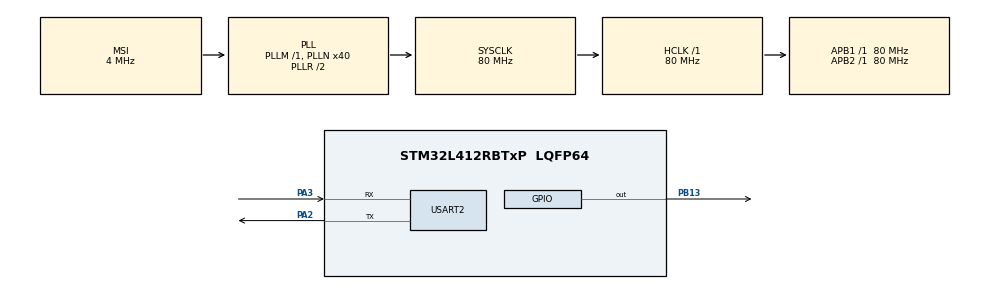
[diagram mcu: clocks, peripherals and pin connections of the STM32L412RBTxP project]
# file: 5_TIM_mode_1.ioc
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Dma.Request0=TIM6_UP
Dma.TIM6_UP.0.Direction=DMA_MEMORY_TO_PERIPH
Dma.TIM6_UP.0.Instance=DMA1_Channel3
Dma.TIM6_UP.0.MemDataAlignment=DMA_MDATAALIGN_BYTE
Dma.TIM6_UP.0.MemInc=DMA_MINC_ENABLE
Dma.TIM6_UP.0.Mode=DMA_CIRCULAR
Dma.TIM6_UP.0.PeriphDataAlignment=DMA_PDATAALIGN_BYTE
Dma.TIM6_UP.0.PeriphInc=DMA_PINC_DISABLE
Dma.TIM6_UP.0.Priority=DMA_PRIORITY_LOW
Mcu.Family=STM32L4
Mcu.Name=STM32L412RBTxP
Mcu.Package=LQFP64
NVIC.DMA1_Channel3_IRQn=true\:0\:0\:false\:false\:true\:false\:true
NVIC.PriorityGroup=NVIC_PRIORITYGROUP_4
NVIC.TIM6_IRQn=true\:0\:0\:false\:false\:true\:true\:true
PA2.Mode=Asynchronous
PA2.Signal=USART2_TX
PA3.Mode=Asynchronous
PA3.Signal=USART2_RX
PB13.Signal=GPIO_Output
ProjectManager.HeapSize=0x200
ProjectManager.StackSize=0x400
ProjectManager.TargetToolchain=STM32CubeIDE
RCC.ADCFreq_Value=80000000
RCC.AHBFreq_Value=80000000
RCC.APB1Freq_Value=80000000
RCC.APB1TimFreq_Value=80000000
RCC.APB2Freq_Value=80000000
RCC.APB2TimFreq_Value=80000000
RCC.CortexFreq_Value=80000000
RCC.HCLKFreq_Value=80000000
RCC.HSE_VALUE=8000000
RCC.HSI48_VALUE=48000000
RCC.HSI_VALUE=16000000
RCC.LSE_VALUE=32768
RCC.MSI_VALUE=4000000
RCC.PLLN=40
RCC.SYSCLKFreq_VALUE=80000000
RCC.SYSCLKSource=RCC_SYSCLKSOURCE_PLLCLK
RCC.USBFreq_Value=4000000
RCC.VCOOutputFreq_Value=160000000
TIM6.Period=10000-1
TIM6.Prescaler=8000-1
USART2.VirtualMode-Asynchronous=VM_ASYNC
VP_TIM6_VS_ClockSourceINT.Mode=Enable_Timer
board=custom

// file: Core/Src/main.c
/* USER CODE BEGIN Header */
/**
  ******************************************************************************
  * @file           : main.c
  * @brief          : Main program body
  ******************************************************************************
  * @attention
  *
  * <h2><center>&copy; Copyright (c) 2021 STMicroelectronics.
  * All rights reserved.</center></h2>
  *
  * This software component is licensed by ST under BSD 3-Clause license,
  * the "License"; You may not use this file except in compliance with the
  * License. You may obtain a copy of the License at:
  *                        opensource.org/licenses/BSD-3-Clause
  *
  ******************************************************************************
  */
/* USER CODE END Header */
#include "main.h"
#include "dma.h"
#include "tim.h"
#include "usart.h"
#include "gpio.h"

void SystemClock_Config(void);

/* USER CODE BEGIN 0 */
uint8_t data[] = "HELLO, DongSik!\r\n";

/* USER CODE END 0 */

int main(void)
{

  /* MCU Configuration--------------------------------------------------------*/

  /* Reset of all peripherals, Initializes the Flash interface and the Systick. */
  HAL_Init();

  /* Configure the system clock */
  SystemClock_Config();

  /* Initialize all configured peripherals */
  MX_GPIO_Init();
  MX_DMA_Init();
  MX_TIM6_Init();
  MX_USART2_UART_Init();
  /* USER CODE BEGIN 2 */
  HAL_TIM_Base_Start_IT(&htim6);

  HAL_DMA_Start(&hdma_tim6_up, (uint32_t)data, (uint32_t)&USART2->TDR, sizeof(data)-1);
  __HAL_TIM_ENABLE_DMA(&htim6, TIM_DMA_UPDATE);

  /* USER CODE END 2 */

  /* Infinite loop */
  while (1)
  {

  }
}

void SystemClock_Config(void)
{
  RCC_OscInitTypeDef RCC_OscInitStruct = {0};
  RCC_ClkInitTypeDef RCC_ClkInitStruct = {0};
  RCC_PeriphCLKInitTypeDef PeriphClkInit = {0};

  /** Configure the main internal regulator output voltage
  */
  if (HAL_PWREx_ControlVoltageScaling(PWR_REGULATOR_VOLTAGE_SCALE1) != HAL_OK)
  {
    Error_Handler();
  }
  /** Initializes the RCC Oscillators according to the specified parameters
  * in the RCC_OscInitTypeDef structure.
  */
  RCC_OscInitStruct.OscillatorType = RCC_OSCILLATORTYPE_MSI;
  RCC_OscInitStruct.MSIState = RCC_MSI_ON;
  RCC_OscInitStruct.MSICalibrationValue = 0;
  RCC_OscInitStruct.MSIClockRange = RCC_MSIRANGE_6;
  RCC_OscInitStruct.PLL.PLLState = RCC_PLL_ON;
  RCC_OscInitStruct.PLL.PLLSource = RCC_PLLSOURCE_MSI;
  RCC_OscInitStruct.PLL.PLLM = 1;
  RCC_OscInitStruct.PLL.PLLN = 40;
  RCC_OscInitStruct.PLL.PLLQ = RCC_PLLQ_DIV2;
  RCC_OscInitStruct.PLL.PLLR = RCC_PLLR_DIV2;
  if (HAL_RCC_OscConfig(&RCC_OscInitStruct) != HAL_OK)
  {
    Error_Handler();
  }
  /** Initializes the CPU, AHB and APB buses clocks
  */
  RCC_ClkInitStruct.ClockType = RCC_CLOCKTYPE_HCLK|RCC_CLOCKTYPE_SYSCLK
                              |RCC_CLOCKTYPE_PCLK1|RCC_CLOCKTYPE_PCLK2;
  RCC_ClkInitStruct.SYSCLKSource = RCC_SYSCLKSOURCE_PLLCLK;
  RCC_ClkInitStruct.AHBCLKDivider = RCC_SYSCLK_DIV1;
  RCC_ClkInitStruct.APB1CLKDivider = RCC_HCLK_DIV1;
  RCC_ClkInitStruct.APB2CLKDivider = RCC_HCLK_DIV1;

  if (HAL_RCC_ClockConfig(&RCC_ClkInitStruct, FLASH_LATENCY_4) != HAL_OK)
  {
    Error_Handler();
  }
  PeriphClkInit.PeriphClockSelection = RCC_PERIPHCLK_USART2;
  PeriphClkInit.Usart2ClockSelection = RCC_USART2CLKSOURCE_PCLK1;
  if (HAL_RCCEx_PeriphCLKConfig(&PeriphClkInit) != HAL_OK)
  {
    Error_Handler();
  }
}

/* USER CODE BEGIN 4 */
void HAL_TIM_PeriodElapsedCallback(TIM_HandleTypeDef *htim)
{
  if(htim->Instance == TIM6)
  {
    HAL_GPIO_TogglePin(GPIOB, GPIO_PIN_13);
  }
}

/* USER CODE END 4 */

void Error_Handler(void)
{
  __disable_irq();
  while (1)
  {
  }
}

/************************ (C) COPYRIGHT STMicroelectronics *****END OF FILE****/
